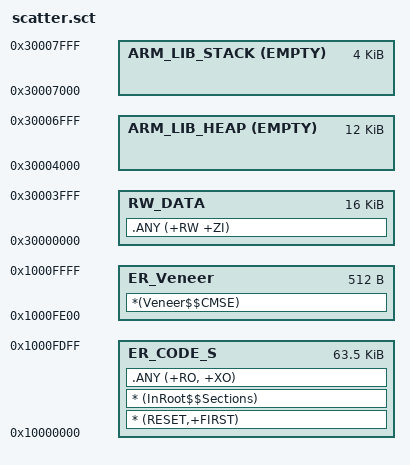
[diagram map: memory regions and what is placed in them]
LR_CODE_S 0x10000000 0xFE00 {
  ER_CODE_S 0x10000000 0xFE00 {
  	* (RESET,+FIRST)
    * (InRoot$$Sections)
    .ANY (+RO, +XO)
  }
  RW_DATA 0x30000000 0x4000 {
    .ANY (+RW +ZI)
  }
  ARM_LIB_HEAP 0x30004000 EMPTY 0x3000 {
  }
  ARM_LIB_STACK 0x30007000 EMPTY 0x1000 {
  }
}
LR_Veneer 0x1000FE00 0x200 {
  ER_Veneer 0x1000FE00 0x200 {
  	*(Veneer$$CMSE)
  }
}
